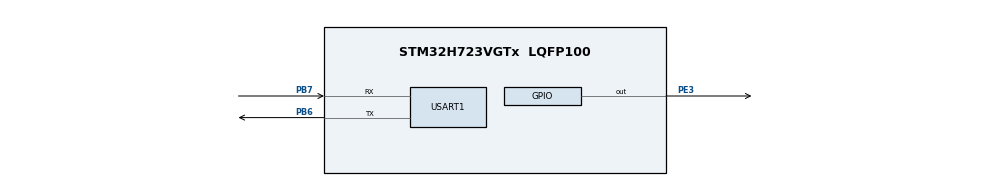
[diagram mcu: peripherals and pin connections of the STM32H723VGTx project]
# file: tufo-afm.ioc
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Mcu.Family=STM32H7
Mcu.Name=STM32H723VGTx
Mcu.Package=LQFP100
NVIC.PriorityGroup=NVIC_PRIORITYGROUP_4
PB6.Mode=Asynchronous
PB6.Signal=USART1_TX
PB7.Mode=Asynchronous
PB7.Signal=USART1_RX
PE3.Signal=GPIO_Output
PH0-OSC_IN.Mode=HSE-External-Oscillator
PH0-OSC_IN.Signal=RCC_OSC_IN
PH1-OSC_OUT.Mode=HSE-External-Oscillator
PH1-OSC_OUT.Signal=RCC_OSC_OUT
ProjectManager.HeapSize=0x200
ProjectManager.StackSize=0x400
ProjectManager.TargetToolchain=CMake
RCC.ADCFreq_Value=50390625
RCC.APB1Freq_Value=137500000
RCC.APB2Freq_Value=137500000
RCC.APB3Freq_Value=137500000
RCC.APB4Freq_Value=137500000
RCC.CortexFreq_Value=550000000
RCC.D1PPRE=RCC_APB3_DIV2
RCC.D2PPRE1=RCC_APB1_DIV2
RCC.D2PPRE2=RCC_APB2_DIV2
RCC.D3PPRE=RCC_APB4_DIV2
RCC.DIVM1=2
RCC.DIVN1=44
RCC.DIVP1=1
RCC.HCLKFreq_Value=275000000
RCC.HPRE=RCC_HCLK_DIV2
RCC.PLLFRACN=0
RCC.PLLSourceVirtual=RCC_PLLSOURCE_HSE
RCC.SYSCLKFreq_VALUE=550000000
RCC.SYSCLKSource=RCC_SYSCLKSOURCE_PLLCLK
RCC.USBFreq_Value=275000000
USART1.VirtualMode-Asynchronous=VM_ASYNC
VP_MEMORYMAP_VS_MEMORYMAP.Mode=CurAppReg
board=custom

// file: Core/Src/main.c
/* USER CODE BEGIN Header */
/**
  ******************************************************************************
  * @file           : main.c
  * @brief          : Main program body
  ******************************************************************************
  * @attention
  *
  * Copyright (c) 2026 STMicroelectronics.
  * All rights reserved.
  *
  * This software is licensed under terms that can be found in the LICENSE file
  * in the root directory of this software component.
  * If no LICENSE file comes with this software, it is provided AS-IS.
  *
  ******************************************************************************
  */
/* USER CODE END Header */
#include "main.h"
#include "stm32h723xx.h"
#include "stm32h7xx_ll_gpio.h"
#include "stm32h7xx_ll_utils.h"
#include "usart.h"
#include "gpio.h"

void SystemClock_Config(void);
/* USER CODE BEGIN PFP */

void tufo_main(void);
/* USER CODE END PFP */

int main(void)
{

  /* MCU Configuration--------------------------------------------------------*/

  /* Reset of all peripherals, Initializes the Flash interface and the Systick. */
  LL_APB4_GRP1_EnableClock(LL_APB4_GRP1_PERIPH_SYSCFG);

  /* System interrupt init*/
  NVIC_SetPriorityGrouping(NVIC_PRIORITYGROUP_4);

  /* SysTick_IRQn interrupt configuration */
  NVIC_SetPriority(SysTick_IRQn, NVIC_EncodePriority(NVIC_GetPriorityGrouping(),15, 0));

  /* Configure the system clock */
  SystemClock_Config();

  /* Initialize all configured peripherals */
  MX_GPIO_Init();
  MX_USART1_UART_Init();

  /* Infinite loop */
  /* USER CODE BEGIN WHILE */
  while (1)
  {
    tufo_main();

    /* USER CODE END WHILE */

  }
}

void SystemClock_Config(void)
{
  LL_FLASH_SetLatency(LL_FLASH_LATENCY_3);
  while(LL_FLASH_GetLatency()!= LL_FLASH_LATENCY_3)
  {
  }
  LL_PWR_ConfigSupply(LL_PWR_LDO_SUPPLY);
  LL_PWR_SetRegulVoltageScaling(LL_PWR_REGU_VOLTAGE_SCALE0);
  while (LL_PWR_IsActiveFlag_VOS() == 0)
  {
  }
  LL_RCC_HSE_Enable();

   /* Wait till HSE is ready */
  while(LL_RCC_HSE_IsReady() != 1)
  {

  }
  LL_RCC_PLL_SetSource(LL_RCC_PLLSOURCE_HSE);
  LL_RCC_PLL1P_Enable();
  LL_RCC_PLL1_SetVCOInputRange(LL_RCC_PLLINPUTRANGE_8_16);
  LL_RCC_PLL1_SetVCOOutputRange(LL_RCC_PLLVCORANGE_WIDE);
  LL_RCC_PLL1_SetM(2);
  LL_RCC_PLL1_SetN(44);
  LL_RCC_PLL1_SetP(1);
  LL_RCC_PLL1_SetQ(2);
  LL_RCC_PLL1_SetR(2);
  LL_RCC_PLL1_Enable();

   /* Wait till PLL is ready */
  while(LL_RCC_PLL1_IsReady() != 1)
  {
  }

   /* Intermediate AHB prescaler 2 when target frequency clock is higher than 80 MHz */
   LL_RCC_SetAHBPrescaler(LL_RCC_AHB_DIV_2);

  LL_RCC_SetSysClkSource(LL_RCC_SYS_CLKSOURCE_PLL1);

   /* Wait till System clock is ready */
  while(LL_RCC_GetSysClkSource() != LL_RCC_SYS_CLKSOURCE_STATUS_PLL1)
  {

  }
  LL_RCC_SetSysPrescaler(LL_RCC_SYSCLK_DIV_1);
  LL_RCC_SetAHBPrescaler(LL_RCC_AHB_DIV_2);
  LL_RCC_SetAPB1Prescaler(LL_RCC_APB1_DIV_2);
  LL_RCC_SetAPB2Prescaler(LL_RCC_APB2_DIV_2);
  LL_RCC_SetAPB3Prescaler(LL_RCC_APB3_DIV_2);
  LL_RCC_SetAPB4Prescaler(LL_RCC_APB4_DIV_2);

  LL_Init1msTick(550000000);

  LL_SetSystemCoreClock(550000000);
}

void Error_Handler(void)
{
  __disable_irq();
  while (1)
  {
  }
}
